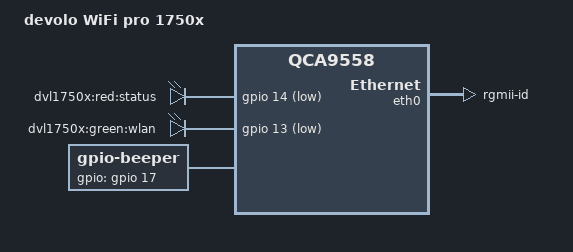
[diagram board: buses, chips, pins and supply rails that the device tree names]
// SPDX-License-Identifier: GPL-2.0-or-later OR MIT
/dts-v1/;

#include "qca9558_devolo_dvl1xxx.dtsi"

/ {
	compatible = "devolo,dvl1750x", "qca,qca9558";
	model = "devolo WiFi pro 1750x";

	aliases {
		led-boot = &led_status_red;
		led-failsafe = &led_status_red;
		led-running = &led_status_red;
		led-upgrade = &led_status_red;
	};

	leds {
		compatible = "gpio-leds";

		led_status_red: status_red {
			/* This LED is not visible on the external casing. */
			label = "dvl1750x:red:status";
			gpios = <&gpio 14 GPIO_ACTIVE_LOW>;
		};

		wlan {
			label = "dvl1750x:green:wlan";
			gpios = <&gpio 13 GPIO_ACTIVE_LOW>;
			linux,default-trigger = "phy0tpt";
		};
	};

	beeper {
		compatible = "gpio-beeper";
		gpios = <&gpio 17 GPIO_ACTIVE_HIGH>;
	};
};

&eth0 {
	pll-data = <0xbe000000 0x80000101 0x80001313>;
	phy-mode = "rgmii-id";
};

&gmac_config {
	rxdv-delay = <3>;
	rxd-delay = <3>;
	txen-delay = <3>;
	txd-delay = <3>;
	rgmii-enabled = <1>;
};
